# R7KA8M2AD register map
Vendor: Renesas Electronics Corporation; Series: RA8; File version: 1.10.02
CPU: CM85 r0p2, little endian, MPU, FPU, VTOR, 4 interrupt priority bits, 96 interrupts
Registers are 32-bit, read-write, reset 0x0 unless marked. A register's access mark holds for its fields unless they carry their own. Offsets are from the block's base; [hi:lo] are bit positions; 'fields as' and 'values as' point back to an identical list.

## CACHE
Base 0x4001C000
Same registers: CACHE_NS 0x5001C000
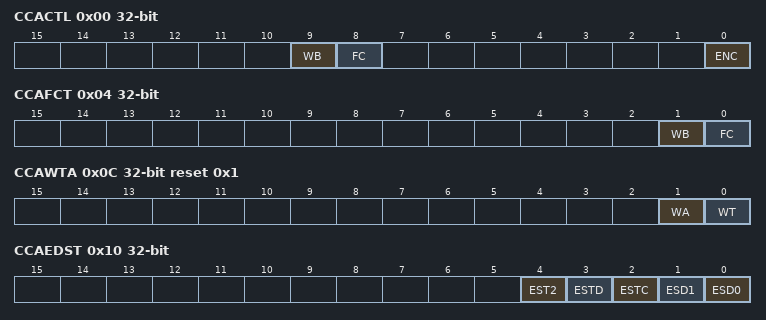
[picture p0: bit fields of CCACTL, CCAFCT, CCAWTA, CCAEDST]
0x00 CCACTL — C-Cache Control Register
  [9] WB — C-cache write-back
    0=No action; 1=C-Cache write-back
  [8] FC — C-Cache flush bit
    0=No action; 1=C-Cache line flush (all lines invalidate)
  [0] ENC — C-cache enable bit
    0=C-Cache disable; 1=C-Cache enable
0x04 CCAFCT — C-Cache Flush Control Register
  [1] WB — C-Cache write-back
    0=No action; 1=C-Cache write-back
  [0] FC — C-Cache flush bit
    0=No action; 1=C-Cache line flush (all lines invalidate)
0x0C CCAWTA reset 0x1 — C-Cache Write Attribute
  [1] WA — C-Cache write-allocation
    0=Always disable write-allocation; 1=Write-allocation enable depends on the cache attribute of the area
  [0] WT — C-Cache write-through
    0=Write-through or write-back depends on the cache attribute of the area; 1=Always write-through mode
0x10 CCAEDST — C-Cache Error Detection Status
  [4] EST2 — C-Cache tag 2-bit error status
    0=ECC 2-bit error was not detected; 1=ECC 2-bit error was detected
  [3] ESTD — C-Cache tag dirty line invalidate status
    0=Dirty line was not invalidated; 1=Dirty line was invalidated
  [2] ESTC — C-Cache tag clean line invalidate status
    0=Clean line was not invalidated; 1=Clean line was invalidated
  [1] ESD1 — C-Cache data error status 1
    values as EST2
  [0] ESD0 — C-Cache data error status 0
    0=ECC 1-bit error was not detected; 1=ECC 1-bit error was detected and corrected
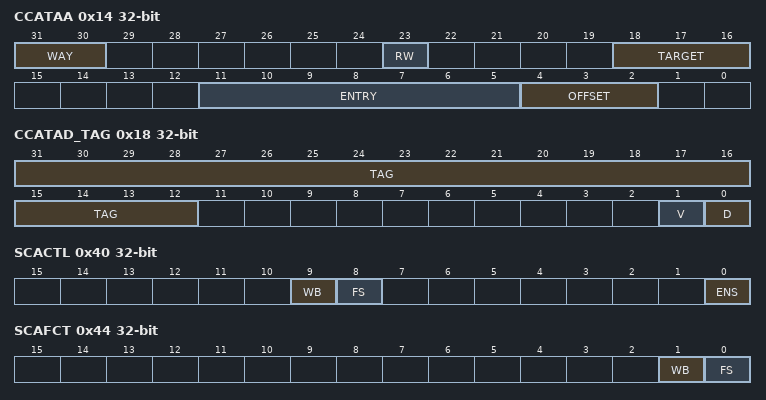
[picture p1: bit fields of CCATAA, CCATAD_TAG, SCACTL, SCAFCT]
0x14 CCATAA — C-Cache Test Access Address
  [31:30] WAY — Address way
  [23] RW — Read write
    0=Read; 1=Write
  [18:16] TARGET — Access target
    0=Cache data read or write; 1=Data ECC code read or write; 2=Tag, V, D read or write; 3=LRU read or write; 4=Tag ECC code read or write; other=Others (Setting prohibited)
  [11:5] ENTRY — Address entry
  [4:2] OFFSET — Address offset
0x18 CCATAD_DATA — C-Cache Test Access Data (DATA)
  [31:0] DATA — C-Cache test access data
0x18 CCATAD_ECC (alternate view of CCATAD_DATA) — C-Cache Test Access Data (ECC)
  [6:0] ECC — C-Cache test access ECC code
0x18 CCATAD_LRU (alternate view of CCATAD_DATA) — C-Cache Test Access Data (LRU)
  [4:0] LRU — C-Cache test access LRU data
0x18 CCATAD_TAG (alternate view of CCATAD_DATA) — C-Cache Test Access Data (TAG)
  [31:12] TAG — C-Cache test access Tag data
  [1] V — C-Cache test access Valid
  [0] D — C-Cache test access Dirty
0x18 CCATAD_TAGECC (alternate view of CCATAD_DATA) — C-Cache Test Access Data (TAGECC)
  [6:0] TAGECC — C-Cache test access Tag ECC code
0x40 SCACTL — S-Cache Control Register
  [9] WB — S-Cache write-back
    0=No action; 1=S-Cache write-back
  [8] FS — S-Cache flush bit
    0=No action; 1=S-Cache line flush (all lines invalidate)
  [0] ENS — S-Cache enable bit
    0=S-Cache disable; 1=S-Cache enable
0x44 SCAFCT — S-Cache Flush Control Register
  [1] WB — S-Cache write-back
    0=No action; 1=S-Cache write-back
  [0] FS — S-Cache flush bit
    0=No action; 1=S-Cache line flush (all lines invalidate)
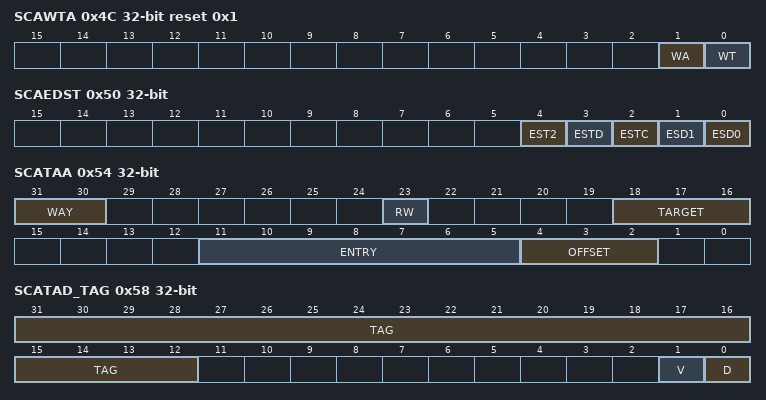
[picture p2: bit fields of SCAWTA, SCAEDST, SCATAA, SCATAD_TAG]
0x4C SCAWTA reset 0x1 — S-Cache Write Attribute
  [1] WA — S-Cache write-allocation
    values as CCAWTA.WA
  [0] WT — S-Cache write-through
    values as CCAWTA.WT
0x50 SCAEDST — S-Cache Error Detection Status
  [4] EST2 — S-Cache Tag 2-bit error status
    values as CCAEDST.EST2
  [3] ESTD — S-Cache Tag dirty line invalidate status
    values as CCAEDST.ESTD
  [2] ESTC — S-Cache Tag clean line invalidate status
    values as CCAEDST.ESTC
  [1] ESD1 — S-Cache data error status 1
    values as CCAEDST.EST2
  [0] ESD0 — S-Cache data error status 0
    0=ECC 1-bit error was not detected; 1=ECC 1-bit error was detected, and corrected
0x54 SCATAA — S-Cache Test Access Address
  [31:30] WAY — Address way
  [23] RW — Read write
    0=read; 1=write
  [18:16] TARGET — Access target
    values as CCATAA.TARGET
  [11:5] ENTRY — Address entry
  [4:2] OFFSET — Address offset
0x58 SCATAD_DATA — S-Cache Test Access Data (DATA)
  [31:0] DATA — S-Cache test access data
0x58 SCATAD_ECC (alternate view of SCATAD_DATA) — S-Cache Test Access Data (ECC)
  [6:0] ECC — S-Cache test access ECC code
0x58 SCATAD_LRU (alternate view of SCATAD_DATA) — S-Cache Test Access Data (LRU)
  [4:0] LRU — S-Cache test access LRU data
0x58 SCATAD_TAG (alternate view of SCATAD_DATA) — S-Cache Test Access Data (TAG)
  [31:12] TAG — S-Cache test access Tag data
  [1] V — S-Cache test access Valid
  [0] D — S-Cache test access Dirty
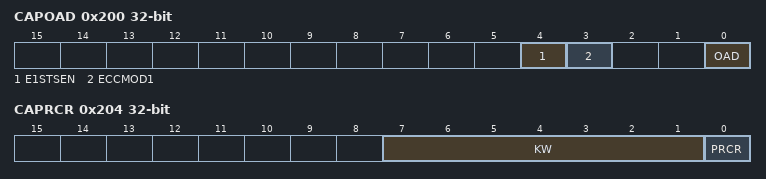
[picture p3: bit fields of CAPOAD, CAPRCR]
0x200 CAPOAD — Cache Parity Error Operation After Detection Register
  [4] E1STSEN — ECC correctable error information update enable
    0=Disable updating of correctable ECC error information; 1=Enable updating of correctable ECC error information
  [3] ECCMOD1 — ECC enable
    0=Disable ECC; 1=Enable ECC
  [0] OAD — Operation after detection bit
    0=Interrupt; 1=Reset
0x204 CAPRCR — Cache Protection Register
  [7:1] KW — Write Key Code bit
  [0] PRCR — Register Write Control bit
    0=Writing to the protected register is disabled; 1=Writing to the protected register is enabled
